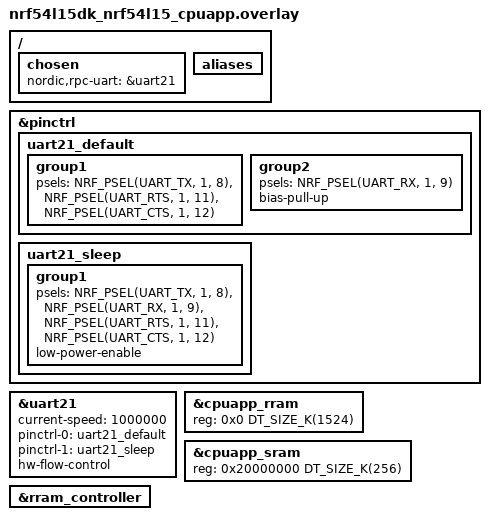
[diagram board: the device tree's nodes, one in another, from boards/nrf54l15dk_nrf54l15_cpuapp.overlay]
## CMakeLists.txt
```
#
# Copyright (c) 2024 Nordic Semiconductor ASA
#
# SPDX-License-Identifier: LicenseRef-Nordic-5-Clause
#
cmake_minimum_required(VERSION 3.20.0)

find_package(Zephyr REQUIRED HINTS $ENV{ZEPHYR_BASE})

project(protocols_serialization_client)

# NORDIC SDK APP START
target_sources(app PRIVATE
    src/main.c
)

zephyr_library_sources_ifdef(CONFIG_OPENTHREAD_RPC src/ot_shell.c)
zephyr_library_sources_ifdef(CONFIG_MPSL_CX_SOFTWARE src/coex_shell.c)
zephyr_library_sources_ifdef(CONFIG_LOG_FORWARDER_RPC src/log_rpc_shell.c)
zephyr_library_sources_ifdef(CONFIG_NFC_RPC src/nfc_shell.c)
zephyr_library_sources_ifdef(CONFIG_BT_THROUGHPUT src/bt_throughput_shell.c)
zephyr_library_sources_ifdef(CONFIG_NRF_RPC_UTILS src/rpc_utils_shell.c)
# NORDIC SDK APP START
```

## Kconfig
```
#
# Copyright (c) 2024 Nordic Semiconductor ASA
#
# SPDX-License-Identifier: LicenseRef-Nordic-5-Clause
#

menu "Protocols serialization client"

config RPC_CRASH_LOG_READ_BUFFER_SIZE
	int "Crash log read buffer size"
	depends on LOG_FORWARDER_RPC
	default 256
	help
	  Size of the stack buffer used for reading a single chunk of the crash
	  log from the server device.

module = NRF_PS_CLIENT
module-str = nrf_ps_client
source "${ZEPHYR_BASE}/subsys/logging/Kconfig.template.log_config"

endmenu # "Protocols serialization client"

if SETTINGS

config ZMS
	default y if (SOC_FLASH_NRF_RRAM || SOC_FLASH_NRF_MRAM)

config NVS
	default y if !(SOC_FLASH_NRF_RRAM || SOC_FLASH_NRF_MRAM)

endif # SETTINGS

menu "Zephyr Kernel"
source "Kconfig.zephyr"
endmenu
```

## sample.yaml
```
sample:
  name: Protocols serialization client sample
  description: Demonstrates serialization of Bluetooth LE and OpenThread API using
    nRF RPC

common:
  sysbuild: true
  build_only: true
  platform_allow:
    - nrf52840dk/nrf52840
    - nrf54l15dk/nrf54l15/cpuapp
  integration_platforms:
    - nrf52840dk/nrf52840
    - nrf54l15dk/nrf54l15/cpuapp
  tags:
    - ci_build
    - ci_samples_nrf_rpc

tests:
  sample.nrf_rpc.protocols_serialization.client.rpc_ble:
    extra_args: >
      SNIPPET="ble"
  sample.nrf_rpc.protocols_serialization.client.rpc_ot:
    extra_args: >
      SNIPPET="openthread"
  sample.nrf_rpc.protocols_serialization.client.rpc:
    extra_args: >
      SNIPPET="ble;openthread;debug;coex;log_rpc"
  sample.nrf_rpc.protocols_serialization.client.rpc_ci:
    extra_args: >
      SNIPPET="ble;openthread;coex;log_rpc;ci-shell;zperf"
    extra_configs:
      - CONFIG_NRF_RPC_UTILS_CRASH_GEN=y
```

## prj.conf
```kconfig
#
# Copyright (c) 2024 Nordic Semiconductor
#
# SPDX-License-Identifier: LicenseRef-Nordic-5-Clause
#
CONFIG_HEAP_MEM_POOL_SIZE=4096

CONFIG_NRF_RPC=y
CONFIG_NRF_RPC_CBOR=y
CONFIG_NRF_RPC_ZCBOR_BACKUPS=1
CONFIG_NRF_RPC_THREAD_STACK_SIZE=4096
CONFIG_NRF_RPC_GROUP_INIT_WAIT_TIME=-1
CONFIG_NRF_RPC_UART_TRANSPORT=y
CONFIG_NRF_RPC_UART_RELIABLE=y

CONFIG_UART_LINE_CTRL=y
CONFIG_UART_INTERRUPT_DRIVEN=y

CONFIG_SHELL=y
CONFIG_LOG=y
CONFIG_LOG_MODE_DEFERRED=y
CONFIG_LOG_BUFFER_SIZE=8192
CONFIG_LOG_FUNC_NAME_PREFIX_DBG=n
CONFIG_LOG_BACKEND_RTT=n
CONFIG_SHELL_LOG_BACKEND=y

CONFIG_NRF_RPC_UTILS=y
CONFIG_NRF_RPC_UTILS_CLIENT=y
CONFIG_NRF_RPC_UTILS_DEV_INFO=y
CONFIG_NRF_RPC_UTILS_REMOTE_SHELL=y
CONFIG_NRF_RPC_UTILS_SYSTEM_HEALTH=y
```

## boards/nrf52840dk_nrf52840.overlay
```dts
/* Copyright (c) 2024 Nordic Semiconductor ASA
 *
 * SPDX-License-Identifier: LicenseRef-Nordic-5-Clause
 */

 / {
	chosen {
		nordic,rpc-uart = &uart1;
	};
};

&uart1 {
	status = "okay";
	hw-flow-control;
	current-speed = <1000000>;
};

&uart1_default {
	group1 {
		psels = <NRF_PSEL(UART_TX, 1, 2)>,
			<NRF_PSEL(UART_RTS, 1, 3)>,
			<NRF_PSEL(UART_CTS, 1, 4)>;
	};
	group2 {
		psels = <NRF_PSEL(UART_RX, 1, 1)>;
		bias-pull-up;
	};
};

&uart1_sleep {
	group1 {
		psels = <NRF_PSEL(UART_RX, 1, 1)>,
			<NRF_PSEL(UART_TX, 1, 2)>,
			<NRF_PSEL(UART_RTS, 1, 3)>,
			<NRF_PSEL(UART_CTS, 1, 4)>;
		low-power-enable;
	};
};
```

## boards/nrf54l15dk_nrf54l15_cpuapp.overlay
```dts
/* Copyright (c) 2024 Nordic Semiconductor ASA
 *
 * SPDX-License-Identifier: LicenseRef-Nordic-5-Clause
 */

 / {
	chosen {
		nordic,rpc-uart = &uart21;
	};

	/* delete all buttons except button0 to free GPIO pins assigned to uart21 below */
	aliases {
		/delete-property/ sw1;
		/delete-property/ sw2;
		/delete-property/ sw3;
	};
};

/delete-node/ &button1;
/delete-node/ &button2;
/delete-node/ &button3;

&pinctrl {
	uart21_default: uart21_default {
		group1 {
			psels = <NRF_PSEL(UART_TX, 1, 8)>,
				<NRF_PSEL(UART_RTS, 1, 11)>,
				<NRF_PSEL(UART_CTS, 1, 12)>;
		};
		group2 {

			psels = <NRF_PSEL(UART_RX, 1, 9)>;
			bias-pull-up;
		};
	};

	uart21_sleep: uart21_sleep {
		group1 {
			psels = <NRF_PSEL(UART_TX, 1, 8)>,
				<NRF_PSEL(UART_RX, 1, 9)>,
				<NRF_PSEL(UART_RTS, 1, 11)>,
				<NRF_PSEL(UART_CTS, 1, 12)>;
			low-power-enable;
		};
	};
};

&uart21 {
	status = "okay";
	current-speed = <1000000>;
	pinctrl-0 = <&uart21_default>;
	pinctrl-1 = <&uart21_sleep>;
	pinctrl-names = "default", "sleep";
	hw-flow-control;
};

/* restore full RRAM and SRAM space - by default some parts are dedicated to FLRP */
&cpuapp_rram {
	reg = <0x0 DT_SIZE_K(1524)>;
};

&cpuapp_sram {
	reg = <0x20000000 DT_SIZE_K(256)>;
	ranges = <0x0 0x20000000  0x40000>;
};

&rram_controller {
	/delete-node/ cpuflpr_sram;
	/delete-node/ cpuflpr_rram;
};
```

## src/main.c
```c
/*
 * Copyright (c) 2024 Nordic Semiconductor ASA
 *
 * SPDX-License-Identifier: LicenseRef-Nordic-5-Clause
 */

#include "ot_shell.h"

#include <zephyr/logging/log.h>

#include <nrf_rpc.h>

LOG_MODULE_REGISTER(nrf_ps_client, CONFIG_NRF_PS_CLIENT_LOG_LEVEL);
NRF_RPC_GROUP_DECLARE(ot_group);
NRF_RPC_GROUP_DECLARE(bt_rpc_grp);

static void err_handler(const struct nrf_rpc_err_report *report)
{
	LOG_ERR("nRF RPC error %d ocurred. See nRF RPC logs for more details", report->code);
}

static void bound_handler(const struct nrf_rpc_group *group)
{
#ifdef CONFIG_OPENTHREAD_RPC_CLIENT
	static bool ot_group_initialized;

	if (group == &ot_group) {
		if (ot_group_initialized) {
			LOG_WRN("OT RPC peer reset detected");
			ot_shell_server_restarted();
			/* The code to restore the state of OT on the server can be added here */
		} else {
			ot_group_initialized = true;
		}
	}
#endif
#ifdef CONFIG_BT_RPC_CLIENT
	static bool bt_group_initialized;

	if (group == &bt_rpc_grp) {
		if (bt_group_initialized) {
			LOG_WRN("BT RPC peer reset detected");
			/* The code to restore the state of BT on the server can be added here */
		} else {
			bt_group_initialized = true;
		}
	}
#endif
}

int main(void)
{
	int ret;

	LOG_INF("Initializing RPC client");

	nrf_rpc_set_bound_handler(bound_handler);

	ret = nrf_rpc_init(err_handler);

	if (ret != 0) {
		LOG_ERR("RPC init failed");
	}

	LOG_INF("RPC client ready");

	return 0;
}
```

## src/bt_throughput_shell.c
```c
/*
 * Copyright (c) 2025 Nordic Semiconductor ASA
 *
 * SPDX-License-Identifier: LicenseRef-Nordic-5-Clause
 */

#include <bluetooth/services/throughput.h>

#include <zephyr/bluetooth/bluetooth.h>
#include <zephyr/bluetooth/conn.h>
#include <zephyr/shell/shell.h>
#include <zephyr/sys/__assert.h>

static const struct bt_data ad[] = {
	BT_DATA_BYTES(BT_DATA_FLAGS, BT_LE_AD_GENERAL | BT_LE_AD_NO_BREDR),
	BT_DATA_BYTES(BT_DATA_UUID128_ALL, BT_UUID_THROUGHPUT_VAL),
};

static const struct bt_data sd[] = {
	BT_DATA(BT_DATA_NAME_COMPLETE, CONFIG_BT_DEVICE_NAME, sizeof(CONFIG_BT_DEVICE_NAME) - 1),
};

static int advertise(void);

static void connected(struct bt_conn *conn, uint8_t hci_err)
{
	int rc;

	if (hci_err) {
		return;
	}

	rc = bt_conn_set_security(conn, BT_SECURITY_L2);
	__ASSERT(rc == 0, "Failed to set BLE security level: %d", rc);
}

static void disconnected(struct bt_conn *conn, uint8_t reason)
{
	ARG_UNUSED(conn);
	ARG_UNUSED(reason);

	advertise();
}

static struct bt_conn_cb conn_cb = {
	.connected = connected,
	.disconnected = disconnected,
};

static int advertise(void)
{
	int rc;

	(void)bt_conn_cb_register(&conn_cb);
	rc = bt_le_adv_start(BT_LE_ADV_CONN_FAST_2, ad, ARRAY_SIZE(ad), sd, ARRAY_SIZE(sd));

	if (rc) {
		(void)bt_conn_cb_unregister(&conn_cb);
	}

	return rc;
}

static int cmd_advertise(const struct shell *sh, size_t argc, char *argv[])
{
	bool start;
	int rc;

	if (!strcmp(argv[1], "on")) {
		start = true;
	} else if (!strcmp(argv[1], "off")) {
		start = false;
	} else {
		shell_error(sh, "Invalid argument: %s", argv[1]);
		return -EINVAL;
	}

	if (start) {
		rc = advertise();
	} else {
		rc = bt_le_adv_stop();
		(void)bt_conn_cb_unregister(&conn_cb);
	}

	if (rc < 0) {
		shell_error(sh, "Failed to %s advertising: %d", start ? "start" : "stop", rc);
		return -ENOEXEC;
	}

	shell_print(sh, "Advertising %s", start ? "started" : "stopped");
	return 0;
}

SHELL_STATIC_SUBCMD_SET_CREATE(bt_throughput_cmds,
			       SHELL_CMD_ARG(advertise, NULL, "on|off", cmd_advertise, 2, 0),
			       SHELL_SUBCMD_SET_END);

SHELL_CMD_ARG_REGISTER(bt_throughput, &bt_throughput_cmds, "BLE throughput commands", NULL, 2, 0);
```

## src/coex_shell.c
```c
/*
 * Copyright (c) 2024 Nordic Semiconductor ASA
 *
 * SPDX-License-Identifier: LicenseRef-Nordic-5-Clause
 */

#include <mpsl/mpsl_cx_software.h>

#include <zephyr/kernel.h>
#include <zephyr/shell/shell.h>

#include <stdlib.h>

static int coex_set_cmd(const struct shell *sh, size_t argc, char *argv[])
{
	mpsl_cx_op_map_t ops = (mpsl_cx_op_map_t)strtoul(argv[1], NULL, 0);
	int64_t timeout_ms = strtoll(argv[2], NULL, 0);

	return mpsl_cx_software_set_granted_ops(ops,
						timeout_ms >= 0 ? K_MSEC(timeout_ms) : K_FOREVER);
}

SHELL_STATIC_SUBCMD_SET_CREATE(coex_cmds,
			       SHELL_CMD_ARG(set, NULL, "<granted_ops> <timeout_ms>", coex_set_cmd,
					     3, 0),
			       SHELL_SUBCMD_SET_END);

SHELL_CMD_ARG_REGISTER(coex, &coex_cmds, "Software Coexistence commands", NULL, 1, 0);
```

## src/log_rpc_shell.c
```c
/*
 * Copyright (c) 2024 Nordic Semiconductor ASA
 *
 * SPDX-License-Identifier: LicenseRef-Nordic-5-Clause
 */

#include <logging/log_rpc.h>

#include <zephyr/kernel.h>
#include <zephyr/shell/shell.h>
#include <zephyr/sys/util.h>

#include <stdlib.h>

#define COREDUMP_LOG_PREFIX   "#CD:"
#define COREDUMP_LOG_BEGIN    "BEGIN#"
#define COREDUMP_LOG_END      "END#"
#define COREDUMP_LOG_LINE_LEN 32

static int cmd_log_rpc_stream_level(const struct shell *sh, size_t argc, char *argv[])
{
	int rc = 0;
	enum log_rpc_level level;

	level = (enum log_rpc_level)shell_strtol(argv[1], 10, &rc);

	if (rc || level < LOG_RPC_LEVEL_NONE || level > LOG_RPC_LEVEL_DBG) {
		shell_error(sh, "Invalid argument: %d", rc);
		return -EINVAL;
	}

	log_rpc_set_stream_level(level);

	return 0;
}

static int cmd_log_rpc_history_level(const struct shell *sh, size_t argc, char *argv[])
{
	int rc = 0;
	enum log_rpc_level level;

	level = (enum log_rpc_level)shell_strtol(argv[1], 10, &rc);

	if (rc || level < LOG_RPC_LEVEL_NONE || level > LOG_RPC_LEVEL_DBG) {
		shell_error(sh, "Invalid argument: %d", rc);
		return -EINVAL;
	}

	log_rpc_set_history_level(level);

	return 0;
}

static const struct shell *shell;

static void history_handler(enum log_rpc_level level, const char *msg, size_t msg_len)
{
	enum shell_vt100_color color;

	if (!msg) {
		shell_print(shell, "Done");
		return;
	}

	switch (level) {
	case LOG_RPC_LEVEL_INF:
		color = SHELL_INFO;
		break;
	case LOG_RPC_LEVEL_WRN:
		color = SHELL_WARNING;
		break;
	case LOG_RPC_LEVEL_ERR:
		color = SHELL_ERROR;
		break;
	default:
		color = SHELL_NORMAL;
		break;
	}

	shell_fprintf(shell, color, "%.*s\n", msg_len, msg);
}

static int cmd_log_rpc_history_fetch(const struct shell *sh, size_t argc, char *argv[])
{
	int rc = 0;

	shell = sh;
	rc = log_rpc_fetch_history(history_handler);

	if (rc) {
		shell_error(sh, "Error: %d", rc);
		return -ENOEXEC;
	}

	return 0;
}

static int cmd_log_rpc_history_stop_fetch(const struct shell *sh, size_t argc, char *argv[])
{
	int rc = 0;
	bool pause;

	pause = shell_strtobool(argv[1], 0, &rc);

	if (rc) {
		shell_error(sh, "Invalid argument: %d", rc);
		return -EINVAL;
	}

	log_rpc_stop_fetch_history(pause);

	return 0;
}

static void history_threshold_reached_handler(void)
{
	shell_print(shell, "History usage threshold reached");
}

static int cmd_log_rpc_history_threshold(const struct shell *sh, size_t argc, char *argv[])
{
	uint32_t threshold;
	int rc = 0;

	if (argc == 0) {
		shell_print(sh, "%u", log_rpc_get_history_usage_threshold());
		return 0;
	}

	threshold = shell_strtoul(argv[1], 0, &rc);

	if (rc) {
		shell_error(sh, "Invalid argument: %d", rc);
		return -EINVAL;
	}

	if (threshold > 100) {
		shell_error(sh, "%u exceeds max value (100)", threshold);
		return -EINVAL;
	}

	shell = sh;
	log_rpc_set_history_usage_threshold(history_threshold_reached_handler, (uint8_t)threshold);

	return 0;
}

static int cmd_log_rpc_crash(const struct shell *sh, size_t argc, char *argv[])
{
	int rc;
	char buffer[CONFIG_RPC_CRASH_LOG_READ_BUFFER_SIZE];
	char line[COREDUMP_LOG_LINE_LEN * 2 + 1];
	size_t offset = 0;

	shell_print(sh, COREDUMP_LOG_PREFIX COREDUMP_LOG_BEGIN);

	while (true) {
		rc = log_rpc_get_crash_dump(offset, buffer, sizeof(buffer));
		if (rc <= 0) {
			break;
		}

		for (int i = 0; i < rc; i += COREDUMP_LOG_LINE_LEN) {
			bin2hex(&buffer[i], MIN(COREDUMP_LOG_LINE_LEN, rc - i), line, sizeof(line));
			shell_print(sh, COREDUMP_LOG_PREFIX "%s", line);
		}

		offset += (size_t)rc;
	}

	shell_print(sh, COREDUMP_LOG_PREFIX COREDUMP_LOG_END);

	if (rc) {
		shell_error(sh, "Error: %d", rc);
		return -ENOEXEC;
	}

	return 0;
}

static int cmd_log_rpc_echo(const struct shell *sh, size_t argc, char *argv[])
{
	int rc = 0;
	enum log_rpc_level level;

	level = (enum log_rpc_level)shell_strtol(argv[1], 10, &rc);

	if (rc) {
		shell_error(sh, "Invalid argument: %d", rc);
		return -EINVAL;
	}

	log_rpc_echo(level, argv[2]);

	return 0;
}

static int cmd_log_rpc_time(const struct shell *sh, size_t argc, char *argv[])
{
	int rc = 0;
	uint64_t time_us;

	if (strcmp(argv[1], "now") == 0) {
		time_us = k_ticks_to_us_near64(k_uptime_ticks());
	} else {
		time_us = shell_strtoull(argv[1], 10, &rc);
	}

	if (rc) {
		shell_error(sh, "Invalid argument: %d", rc);
		return -EINVAL;
	}

	log_rpc_set_time(time_us);

	return 0;
}

SHELL_STATIC_SUBCMD_SET_CREATE(
	log_rpc_cmds,
	SHELL_CMD_ARG(stream_level, NULL, "Set log streaming level <0-4>", cmd_log_rpc_stream_level,
		      2, 0),
	SHELL_CMD_ARG(history_level, NULL, "Set log history level <0-4>", cmd_log_rpc_history_level,
		      2, 0),
	SHELL_CMD_ARG(history_fetch, NULL, "Fetch log history", cmd_log_rpc_history_fetch, 1, 0),
	SHELL_CMD_ARG(history_stop_fetch, NULL, "Stop log history transfer <pause?>",
		      cmd_log_rpc_history_stop_fetch, 2, 0),
	SHELL_CMD_ARG(history_threshold, NULL, "Get or set history usage threshold [0-100]",
		      cmd_log_rpc_history_threshold, 1, 1),
	SHELL_CMD_ARG(crash, NULL, "Retrieve remote device crash log", cmd_log_rpc_crash, 1, 0),
	SHELL_CMD_ARG(echo, NULL, "Generate log message on remote <0-4> <msg>", cmd_log_rpc_echo, 3,
		      0),
	SHELL_CMD_ARG(time, NULL, "Set current time <time_us|now>", cmd_log_rpc_time, 2, 0),
	SHELL_SUBCMD_SET_END);

SHELL_CMD_ARG_REGISTER(log_rpc, &log_rpc_cmds, "RPC logging commands", NULL, 1, 0);
```

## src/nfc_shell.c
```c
/*
 * Copyright (c) 2024 Nordic Semiconductor ASA
 *
 * SPDX-License-Identifier: LicenseRef-Nordic-5-Clause
 */

#include <nfc_t2t_lib.h>
#include <nfc/ndef/msg.h>
#include <nfc/ndef/text_rec.h>

#include <zephyr/shell/shell.h>
#include <zephyr/sys/__assert.h>

#define NFC_MESSAGE_BUFFER 128

static uint8_t *default_message = "Hello World!";
static uint8_t *default_code = "en";

/* Buffer used to hold an NFC NDEF message. */
static uint8_t ndef_msg_buf[NFC_MESSAGE_BUFFER];

NFC_NDEF_MSG_DEF(msg_descr, 1);

static int message_encode(char *msg, uint32_t *length)
{
	int err;

	/* Create NFC NDEF text record description */
	NFC_NDEF_TEXT_RECORD_DESC_DEF(record, UTF_8, default_code, strlen(default_code), msg,
				      strlen(msg));

	/* Clear the message description. */
	nfc_ndef_msg_clear(&NFC_NDEF_MSG(msg_descr));

	/* Add text records to NDEF text message */
	err = nfc_ndef_msg_record_add(&NFC_NDEF_MSG(msg_descr), &NFC_NDEF_TEXT_RECORD_DESC(record));
	if (err < 0) {
		return err;
	}

	err = nfc_ndef_msg_encode(&NFC_NDEF_MSG(msg_descr), ndef_msg_buf, length);
	__ASSERT(*length <= NFC_MESSAGE_BUFFER, "message too long");

	return err;
}

static void nfc_callback(void *context, nfc_t2t_event_t event, const uint8_t *data,
			 size_t data_length)
{
	static const char *const event_str[] = {"none", "field_on", "field_off", "data_read",
						"stopped"};
	const struct shell *sh = (const struct shell *)context;

	switch (event) {
	case NFC_T2T_EVENT_NONE:
	case NFC_T2T_EVENT_FIELD_ON:
	case NFC_T2T_EVENT_FIELD_OFF:
	case NFC_T2T_EVENT_DATA_READ:
	case NFC_T2T_EVENT_STOPPED:
		shell_print(sh, "NFC T2T event: %s", event_str[event]);
		break;
	default:
		shell_print(sh, "Unknown NFC event");
	}
}

static int nfc_init_cmd(const struct shell *sh, size_t argc, char *argv[])
{
	int err = nfc_t2t_setup(nfc_callback, (void *)sh);
	uint32_t length = sizeof(ndef_msg_buf);

	if (err) {
		shell_print(sh, "Cannot setup NFC T2T library. err: %u", err);
		return -ENOEXEC;
	}

	if (message_encode(default_message, &length) < 0) {
		shell_print(sh, "Cannot encode message.");
		return -ENOEXEC;
	}

	/* Set created message as the NFC payload */
	if (nfc_t2t_payload_set(ndef_msg_buf, length) < 0) {
		shell_print(sh, "Cannot set payload.");
		return -ENOEXEC;
	}

	return 0;
}

static int nfc_release_cmd(const struct shell *sh, size_t argc, char *argv[])
{
	int err = nfc_t2t_done();

	if (err) {
		shell_print(sh, "Cannot release NFC. err: %u", err);
		return -ENOEXEC;
	}

	return 0;
}

static int nfc_start_cmd(const struct shell *sh, size_t argc, char *argv[])
{
	int err = nfc_t2t_emulation_start();

	if (err) {
		shell_print(sh, "Cannot activate NFC frontend. err: %u", err);
		return -ENOEXEC;
	}

	return 0;
}

static int nfc_stop_cmd(const struct shell *sh, size_t argc, char *argv[])
{
	int err = nfc_t2t_emulation_stop();

	if (err) {
		shell_print(sh, "Cannot deactivate NFC frontend. err: %u", err);
		return -ENOEXEC;
	}

	return 0;
}

static int nfc_set_msg_cmd(const struct shell *sh, size_t argc, char *argv[])
{
	uint32_t length = sizeof(ndef_msg_buf);

	if (message_encode(argv[1], &length) < 0) {
		shell_print(sh, "Cannot encode message.");
		return -ENOEXEC;
	}

	/* Set created message as the NFC payload */
	if (nfc_t2t_payload_set(ndef_msg_buf, length) < 0) {
		shell_print(sh, "Cannot set payload.");
		return -ENOEXEC;
	}

	return 0;
}

SHELL_STATIC_SUBCMD_SET_CREATE(
	nfc_cmds, SHELL_CMD_ARG(init, NULL, "Initialize NFC", nfc_init_cmd, 1, 0),
	SHELL_CMD_ARG(release, NULL, "Release NFC", nfc_release_cmd, 1, 0),
	SHELL_CMD_ARG(start, NULL, "Activate the NFC frontend", nfc_start_cmd, 1, 0),
	SHELL_CMD_ARG(stop, NULL, "Deactivate the NFC frontend", nfc_stop_cmd, 1, 0),
	SHELL_CMD_ARG(set_new_msg, NULL, "Set the new message to NFC payload", nfc_set_msg_cmd, 2,
		      0),
	SHELL_SUBCMD_SET_END);

SHELL_CMD_ARG_REGISTER(nfc, &nfc_cmds, "NFC demonstration commands", NULL, 1, 0);
```

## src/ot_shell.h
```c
/*
 * Copyright (c) 2024 Nordic Semiconductor ASA
 *
 * SPDX-License-Identifier: LicenseRef-Nordic-5-Clause
 */

#ifndef OT_SHELL_H_
#define OT_SHELL_H_

void ot_shell_server_restarted(void);

#endif
```

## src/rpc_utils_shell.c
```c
/*
 * Copyright (c) 2024 Nordic Semiconductor ASA
 *
 * SPDX-License-Identifier: LicenseRef-Nordic-5-Clause
 */

#include <zephyr/shell/shell.h>
#include <nrf_rpc/rpc_utils/crash_gen.h>
#include <nrf_rpc/rpc_utils/dev_info.h>
#include <nrf_rpc/rpc_utils/remote_shell.h>
#include <nrf_rpc/rpc_utils/system_health.h>

#if defined(CONFIG_NRF_RPC_UTILS_DEV_INFO)
static int remote_version_cmd(const struct shell *sh, size_t argc, char *argv[])
{
	char *version = nrf_rpc_get_ncs_commit_sha();

	if (!version) {
		shell_error(sh, "Failed to get remote version");
		return -ENOEXEC;
	}

	shell_print(sh, "Remote version: %s", version);

	k_free(version);

	return 0;
}
#endif

#if defined(CONFIG_NRF_RPC_UTILS_REMOTE_SHELL)
static int remote_shell_cmd(const struct shell *sh, size_t argc, char *argv[])
{
	char *output = nrf_rpc_invoke_remote_shell_cmd(argc - 1, argv + 1);

	if (!output) {
		shell_error(sh, "Failed to invoke remote shell command");
		return -ENOEXEC;
	}

	shell_print(sh, "%s", output);

	k_free(output);

	return 0;
}
#endif /* CONFIG_NRF_RPC_UTILS_REMOTE_SHELL */

#if defined(CONFIG_NRF_RPC_UTILS_CRASH_GEN)
static int cmd_assert(const struct shell *sh, size_t argc, char *argv[])
{
	int rc = 0;
	uint32_t delay = 0;

	if (argc > 1) {
		delay = shell_strtol(argv[1], 10, &rc);
	}

	if (rc) {
		shell_print(sh, "Invalid argument: %s", argv[1]);
		return -EINVAL;
	}

	nrf_rpc_crash_gen_assert(delay);

	return 0;
}

static int cmd_hard_fault(const struct shell *sh, size_t argc, char *argv[])
{
	int rc = 0;
	uint32_t delay = 0;

	if (argc > 1) {
		delay = shell_strtol(argv[1], 10, &rc);
	}

	if (rc) {
		shell_print(sh, "Invalid argument: %s", argv[1]);
		return -EINVAL;
	}

	nrf_rpc_crash_gen_hard_fault(delay);

	return 0;
}

static int cmd_stack_overflow(const struct shell *sh, size_t argc, char *argv[])
{
	int rc = 0;
	uint32_t delay = 0;

	if (argc > 1) {
		delay = shell_strtol(argv[1], 10, &rc);
	}

	if (rc) {
		shell_print(sh, "Invalid argument: %s", argv[1]);
		return -EINVAL;
	}

	nrf_rpc_crash_gen_stack_overflow(delay);

	return 0;
}
#endif /* CONFIG_NRF_RPC_UTILS_CRASH_GEN */

#if defined(CONFIG_NRF_RPC_UTILS_SYSTEM_HEALTH)
static int cmd_system_health(const struct shell *sh, size_t argc, char *argv[])
{
	struct nrf_rpc_system_health health;

	nrf_rpc_system_health_get(&health);

	shell_print(sh, "Hung threads: %u", health.hung_threads);

	return 0;
}
#endif /* CONFIG_NRF_RPC_UTILS_SYSTEM_HEALTH */

SHELL_STATIC_SUBCMD_SET_CREATE(
	util_cmds,
#if defined(CONFIG_NRF_RPC_UTILS_DEV_INFO)
	SHELL_CMD_ARG(remote_version, NULL, "Get server version", remote_version_cmd, 1, 0),
#endif
#if defined(CONFIG_NRF_RPC_UTILS_REMOTE_SHELL)
	SHELL_CMD_ARG(remote_shell, NULL, "Call remote shell command", remote_shell_cmd, 2, 255),
#endif
#if defined(CONFIG_NRF_RPC_UTILS_CRASH_GEN)
	SHELL_CMD_ARG(assert, NULL, "Invoke assert", cmd_assert, 1, 1),
	SHELL_CMD_ARG(hard_fault, NULL, "Invoke hard fault", cmd_hard_fault, 1, 1),
	SHELL_CMD_ARG(stack_overflow, NULL, "Invoke stack overflow", cmd_stack_overflow, 1, 1),
#endif
#if defined(CONFIG_NRF_RPC_UTILS_SYSTEM_HEALTH)
	SHELL_CMD_ARG(system_health, NULL, "Get system health", cmd_system_health, 0, 0),
#endif
	SHELL_SUBCMD_SET_END);

SHELL_CMD_ARG_REGISTER(rpc, &util_cmds, "nRF RPC utility commands", NULL, 1, 0);
```
